# FM33FK5XX register map
File version: 1.0
CPU: Cortex-M33 r1p0, little endian, MPU, FPU, 3 interrupt priority bits
Registers are 32-bit, read-write, reset 0x0 unless marked. A register's access mark holds for its fields unless they carry their own. Offsets are from the block's base; [hi:lo] are bit positions; {n}, {i} and the like mark numbered series.

## CRC — CRC module information
Base 0x40018000
0x00 DR reset 0xFFFFFFFF — CRCDataRegister
  [31:0] DR — DR field description
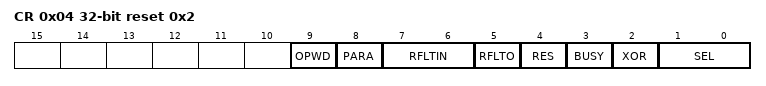
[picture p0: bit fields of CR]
0x04 CR access per field reset 0x2 — CRCControlRegister
  [9] OPWD rw — OPWD field description
  [8] PARA rw — PARA field description
  [7:6] RFLTIN rw — RFLTIN field description
  [5] RFLTO rw — RFLTO field description
  [4] RES ro — RES field description
  [3] BUSY ro — BUSY field description
  [2] XOR rw — XOR field description
  [1:0] SEL rw — SEL field description
0x08 LFSR reset 0xFFFFFFFF — CRCLinearFeedbackShiftRegister
  [31:0] LFSR — LFSR field description
0x0C XOR — CRCoutputXORRegister
  [31:0] XOR — XOR field description
0x1C POLY reset 0x1021 — CRCPolynominalRegister
  [31:0] POLY — POLY field description

## GPTIM0 — GPTIM0 module information
Base 0x40013800
Same registers: GPTIM1 0x40013C00, GPTIM2 0x40014000
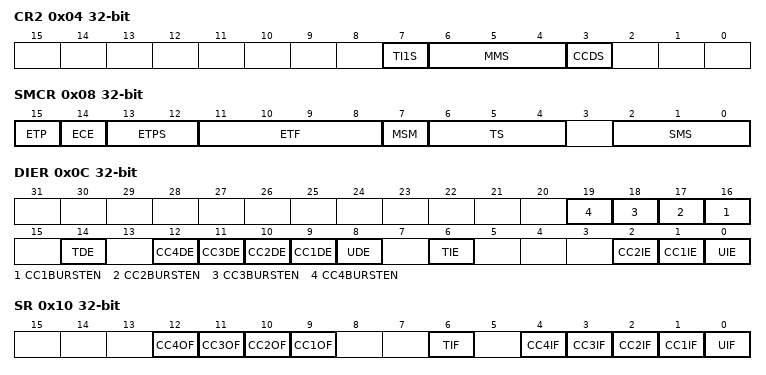
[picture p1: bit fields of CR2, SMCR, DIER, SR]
0x04 CR2
  [7] TI1S — TI1S field description
  [6:4] MMS — MMS field description
  [3] CCDS — CCDS field description
0x08 SMCR
  [15] ETP — ETP field description
  [14] ECE — ECE field description
  [13:12] ETPS — ETPS field description
  [11:8] ETF — ETF field description
  [7] MSM — MSM field description
  [6:4] TS — TS field description
  [2:0] SMS — SMS field description
0x0C DIER
  [n+15] CC{n}BURSTEN (n=1..4) — CC{n}BURSTEN field description
  [14] TDE — TDE field description
  [n+8] CC{n}DE (n=1..4) — CC{n}DE field description
  [8] UDE — UDE field description
  [6] TIE — TIE field description
  [2] CC2IE — CC2IE field description
  [1] CC1IE — CC1IE field description
  [0] UIE — UIE field description
0x10 SR
  [n+8] CC{n}OF (n=1..4) — CC{n}OF field description
  [6] TIF — TIF field description
  [n] CC{n}IF (n=1..4) — CC{n}IF field description
  [0] UIF — UIF field description
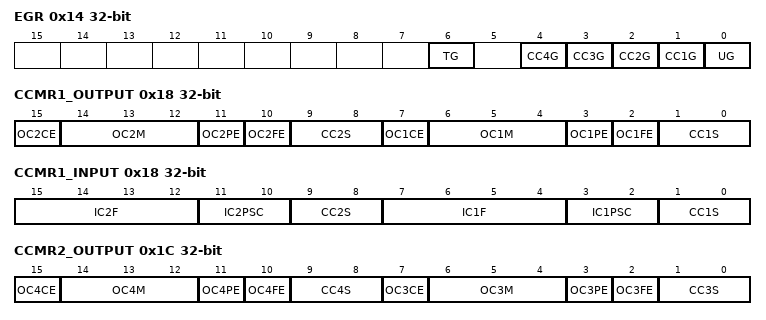
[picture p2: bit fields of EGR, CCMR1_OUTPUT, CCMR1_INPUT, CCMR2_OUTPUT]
0x14 EGR wo
  [6] TG — TG field description
  [n] CC{n}G (n=1..4) — CC{n}G field description
  [0] UG — UG field description
0x18 CCMR1_OUTPUT
  [15] OC2CE — OC2CE field description
  [14:12] OC2M — OC2M field description
  [11] OC2PE — OC2PE field description
  [10] OC2FE — OC2FE field description
  [9:8] CC2S — CC2S field description
  [7] OC1CE — OC1CE field description
  [6:4] OC1M — OC1M field description
  [3] OC1PE — OC1PE field description
  [2] OC1FE — OC1FE field description
  [1:0] CC1S — CC1S field description
0x18 CCMR1_INPUT (alternate view of CCMR1_OUTPUT)
  [15:12] IC2F — IC2F field description
  [11:10] IC2PSC — IC2PSC field description
  [9:8] CC2S — CC2S field description
  [7:4] IC1F — IC1F field description
  [3:2] IC1PSC — IC1PSC field description
  [1:0] CC1S — CC1S field description
0x1C CCMR2_OUTPUT
  [15] OC4CE — OC4CE field description
  [14:12] OC4M — OC4M field description
  [11] OC4PE — OC4PE field description
  [10] OC4FE — OC4FE field description
  [9:8] CC4S — CC4S field description
  [7] OC3CE — OC3CE field description
  [6:4] OC3M — OC3M field description
  [3] OC3PE — OC3PE field description
  [2] OC3FE — OC3FE field description
  [1:0] CC3S — CC3S field description
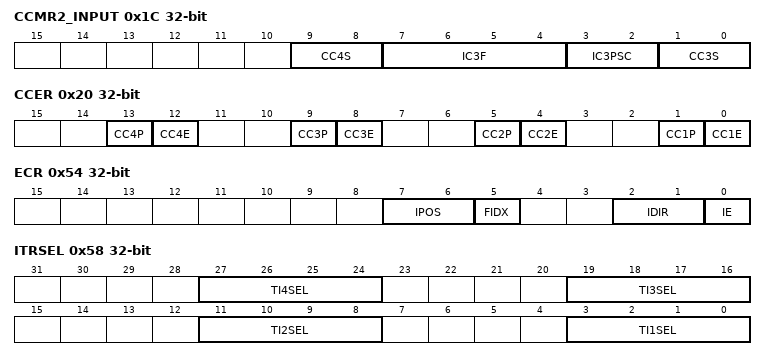
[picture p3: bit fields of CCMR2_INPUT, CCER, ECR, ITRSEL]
0x1C CCMR2_INPUT (alternate view of CCMR2_OUTPUT)
  [9:8] CC4S — CC4S field description
  [7:4] IC3F — IC3F field description
  [3:2] IC3PSC — IC3PSC field description
  [1:0] CC3S — CC3S field description
0x20 CCER
  [4n-3] CC{n}P (n=1..4) — CC{n}P field description
  [4n-4] CC{n}E (n=1..4) — CC{n}E field description
0x24 CNT
  [15:0] CNT — CNT field description
0x28 PSC
  [15:0] PSC — PSC field description
0x2C ARR reset 0xFFFF
  [15:0] ARR — ARR field description
{0x30+4i} CCR{i} (i=1..4)
  [15:0] CCR{i} — CCR{i} field description
0x54 ECR
  [7:6] IPOS — IPOS field description
  [5] FIDX — FIDX field description
  [2:1] IDIR — IDIR field description
  [0] IE — IE field description
0x58 ITRSEL
  [8n-5:8n-8] TI{n}SEL (n=1..4) — TI{n}SEL field description
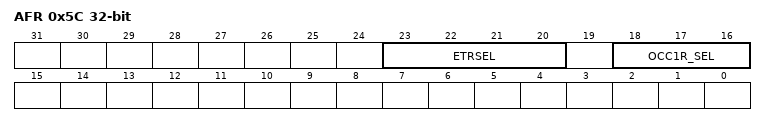
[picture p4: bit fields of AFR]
0x5C AFR
  [23:20] ETRSEL — ETRSEL field description
  [18:16] OCC1R_SEL — OCC1R_SEL field description
0xFC DMAR
  [15:0] DMAR — DMAR field description
